# SAM9X60 device description
Architecture: ARM926EJS; Family: SAM9; Series: SAM9X
Registers are 32-bit, read-write, no defined reset value unless marked. A register's access mark holds for its fields unless they carry their own. Offsets are from the block's base; [hi:lo] are bit positions; lines under a group give offsets from that group; {n}, {i} and the like mark numbered series.

## SMC — Static Memory Controller
Instances: SMC 0xFFFFEA00
{0x0+0x10*i} SMC_CS_NUMBER[{i}] (i=0..5) group
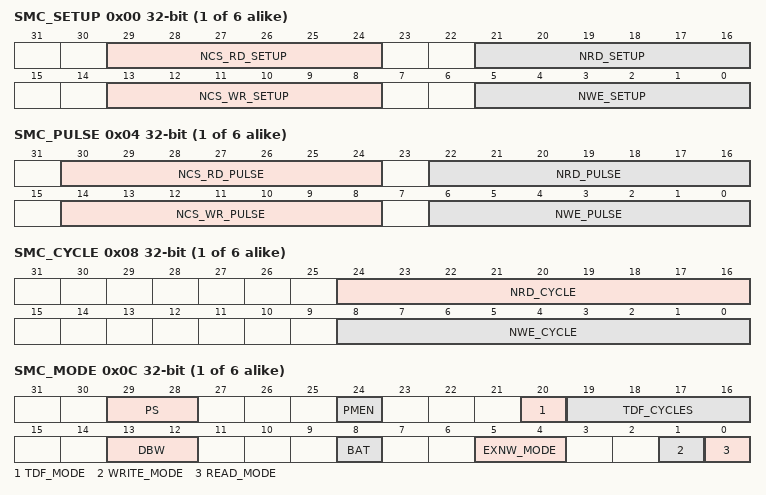
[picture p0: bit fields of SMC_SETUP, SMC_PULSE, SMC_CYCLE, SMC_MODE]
  0x00 SMC_SETUP
    [29:24] NCS_RD_SETUP — NCS Setup Length in READ Access
    [21:16] NRD_SETUP — NRD Setup Length
    [13:8] NCS_WR_SETUP — NCS Setup Length in WRITE Access
    [5:0] NWE_SETUP — NWE Setup Length
  0x04 SMC_PULSE
    [30:24] NCS_RD_PULSE — NCS Pulse Length in READ Access
    [22:16] NRD_PULSE — NRD Pulse Length
    [14:8] NCS_WR_PULSE — NCS Pulse Length in WRITE Access
    [6:0] NWE_PULSE — NWE Pulse Length
  0x08 SMC_CYCLE
    [24:16] NRD_CYCLE — Total Read Cycle Length
    [8:0] NWE_CYCLE — Total Write Cycle Length
  0x0C SMC_MODE
    [29:28] PS — Page Size
      0=BYTE_4 (4-byte page); 1=BYTE_8 (8-byte page); 2=BYTE_16 (16-byte page); 3=BYTE_32 (32-byte page)
    [24] PMEN — Page Mode Enabled
    [20] TDF_MODE — TDF Optimization
    [19:16] TDF_CYCLES — Data Float Time
    [13:12] DBW — Data Bus Width
      0=BIT_8 (8-bit bus); 1=BIT_16 (16-bit bus); 2=BIT_32 (32-bit bus)
    [8] BAT — Byte Access Type
      0=BYTE_SELECT (Byte select access type: - Write operation is controlled using NCS, NWE, NBS0, NBS1, NBS2 and NBS3 - Read operation is controlled using NCS, NRD, NBS0, NBS1, NBS2 and NBS3); 1=BYTE_WRITE (Byte write access type: - Write operation is controlled using NCS, NWR0, NWR1, NWR2, NWR3 - Read operation is controlled using NCS and NRD)
    [5:4] EXNW_MODE — NWAIT Mode
      0=DISABLED (Disabled Mode-The NWAIT input signal is ignored on the corresponding Chip Select.); 2=FROZEN (Frozen Mode-If asserted, the NWAIT signal freezes the current read or write cycle. After deassertion, the read/write cycle is resumed from the point where it was stopped.); 3=READY (Ready Mode-The NWAIT signal indicates the availability of the external device at the end of the pulse of the controlling read or write signal, to complete the access. If high, the access normally completes. If low, the access is extended until NWAIT returns high.)
    [1] WRITE_MODE — Selection of the Control Signal for Write Operation
      0=NCS_CTRL (Write operation controlled by NCS signal-If TDF optimization is enabled (TDF_MODE = 1), TDF wait states will be inserted after the setup of NCS.); 1=NWE_CTRL (Write operation controlled by NWE signal-If TDF optimization is enabled (TDF_MODE = 1), TDF wait states will be inserted after the setup of NWE.)
    [0] READ_MODE — Selection of the Control Signal for Read Operation
      0=NCS_CTRL (Read operation controlled by NCS signal - If TDF cycles are programmed, the external bus is marked busy after the rising edge of NCS. - If TDF optimization is enabled (TDF_MODE = 1), TDF wait states are inserted after the setup of NCS.); 1=NRD_CTRL (Read operation controlled by NRD signal - If TDF cycles are programmed, the external bus is marked busy after the rising edge of NRD. - If TDF optimization is enabled (TDF_MODE = 1), TDF wait states are inserted after the setup of NRD.)
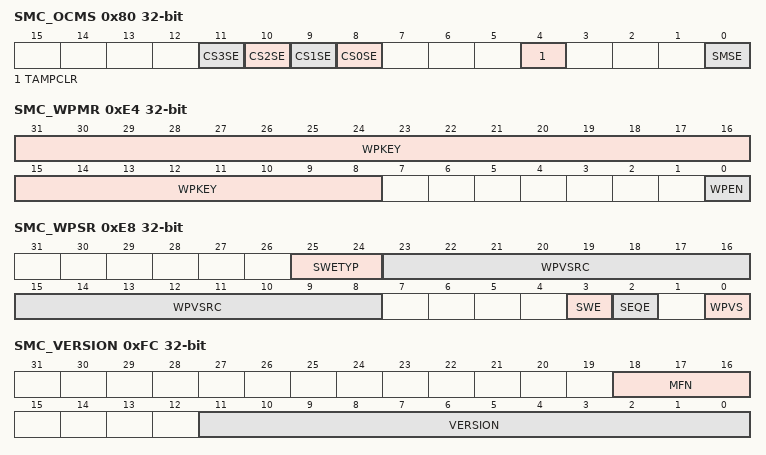
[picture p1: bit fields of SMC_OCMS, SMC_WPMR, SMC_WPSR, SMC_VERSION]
0x80 SMC_OCMS — SMC Off-Chip Memory Scrambling Register
  [n+8] CS{n}SE (n=0..3) — Chip Select (x = 0 to 3) Scrambling Enable
  [4] TAMPCLR — Tamper Clear Enable
  [0] SMSE — Static Memory Controller Scrambling Enable
0x84 SMC_KEY1 wo — SMC Off-Chip Memory Scrambling KEY1 Register
  [31:0] KEY1 — Off-Chip Memory Scrambling (OCMS) Key Part 1
0x88 SMC_KEY2 wo — SMC Off-Chip Memory Scrambling KEY2 Register
  [31:0] KEY2 — Off-Chip Memory Scrambling (OCMS) Key Part 2
0x90 SMC_SRIER — SMC Safety Report Interrupt Enable Register
  [0] SRIE — Safety Report Interrupt Enable
0xE4 SMC_WPMR — SMC Write Protection Mode Register
  [31:8] WPKEY — Write Protection Key
    0x534D43=PASSWD (Writing any other value in this field aborts the write operation of bit WPEN. Always reads as 0.)
  [0] WPEN — Write Protection Enable
0xE8 SMC_WPSR ro — SMC Write Protection Status Register
  [25:24] SWETYP — Software Error Type (Cleared on read)
    0=READ_WO (A write-only register has been read.); 1=WRITE_RO (A write access has been performed on a read-only register.); 2=UNDEF_RW (Access to an undefined address.)
  [23:8] WPVSRC — Write Protection Violation Source
  [3] SWE — Software Control Error (Cleared on read)
  [2] SEQE — Internal Sequencer Error (Cleared on read)
  [0] WPVS — Write Protection Violation Status (Cleared on read)
0xFC SMC_VERSION ro
  [18:16] MFN — Metal Fix Number
  [11:0] VERSION — Hardware Version Number
